VERSION "HINBNNNYYNNNYYNNNNNNNNNNNNYNNNYYYNNYNNNNNN/4//%%/4/'%**4NNN///"

NS_ :

BS_:

BU_: PSTED VMU
VAL_TABLE_ PSTED_IsolationControl 1 "Disable" 0 "Enable" ;
VAL_TABLE_ Wire_Isolation_Status 6 "Isolation failure flag (filtered & unfiltered)" 5 "Isolation failure flag (unfiltered) & reserved" 4 "Isolation failure flag (unfiltered)" 3 "Isolation failure flag & reserved" 2 "Isolation failure flag" 1 "reserved" 0 "ok" ;
VAL_TABLE_ DeviceStatus 15 "Overheat & Warning & Failure & Operating" 14 "Overheat & Warning & Failure" 13 "Overheat & Warning & Operating" 12 "Overheat & Warning" 11 "Overheat & Failure & Operating" 10 "Overheat & Failure" 9 "Overheat & Operating" 8 "Overheat" 7 "Warning & Failure & Operating" 6 "Warning & Failure" 5 "Warning & Operating" 4 "Warning" 3 "Failure & Operating" 2 "Failure" 1 "Operating" 0 "Idle" ;
VAL_TABLE_ Enable 1 "Enable" 0 "Disable" ;
VAL_TABLE_ Heartbeat_State 127 "PreOperational" 5 "Operational" 4 "Stopped" 0 "Bootup" ;

BO_ 1793 PSTED_Heartbeat: 1 Vector__XXX
 SG_ Toggle : 7|1@1+ (1,0) [0|1] "" Vector__XXX
 SG_ State : 0|7@1+ (1,0) [0|127] "" Vector__XXX

BO_ 660 PSTED_RefTorque: 8 VMU
 SG_ PSTED_RefFullCurrent : 16|16@1- (0.019837031,0) [-650.019831808|649.999994777] "A" Vector__XXX
 SG_ PSTED_RefElectricAngleOffset : 40|16@1- (0.010986663411359,0) [-360.010986663411|360] "deg" Vector__XXX
 SG_ PSTED_RefFluxCurrent : 32|8@1+ (0.2,0) [0|51] "A" Vector__XXX
 SG_ PSTED_RefTorque_16bit : 16|16@1- (0.0030518509476,0) [-100.003051850957|100.000000000009] "%"  PSTED
 SG_ PSTED_RefTorque_cmd : 0|8@1- (0.78740157,0) [-100.78740096|99.99999939] "%"  PSTED

BO_ 1153 PSTED_Errors: 8 PSTED
 SG_ PSTED_Warnings : 48|16@1+ (1,0) [0|65535] ""  VMU
 SG_ PSTED_ErrorFlags : 0|48@1+ (1,0) [0|281474976710655] ""  VMU

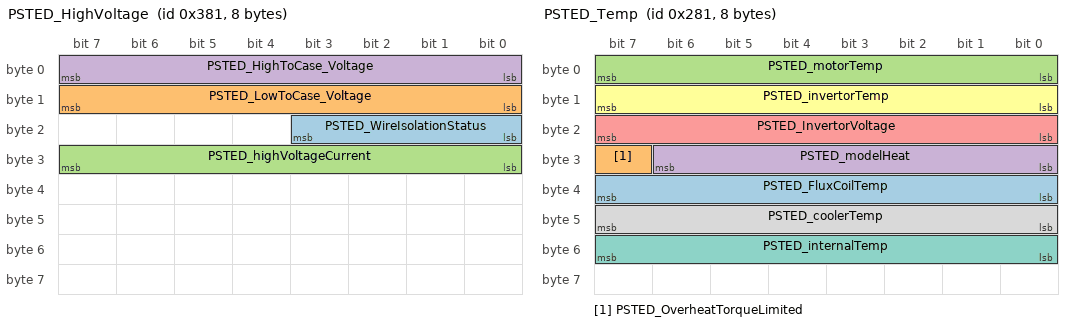
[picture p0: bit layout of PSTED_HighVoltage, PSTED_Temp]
BO_ 897 PSTED_HighVoltage: 8 PSTED
 SG_ PSTED_WireIsolationStatus : 16|4@1+ (1,0) [0|15] ""  VMU
 SG_ PSTED_LowToCase_Voltage : 8|8@1+ (6.35294117,0) [0|1619.99999835] "V"  VMU
 SG_ PSTED_highVoltageCurrent : 24|8@1- (1.5748031496,0) [-201.5748031488|199.9999999992] "A"  VMU
 SG_ PSTED_HighToCase_Voltage : 0|8@1+ (6.35294117,0) [0|1619.99999835] "V"  VMU

BO_ 641 PSTED_Temp: 8 PSTED
 SG_ PSTED_FluxCoilTemp : 32|8@1+ (1,-40) [-40|215] "°C" Vector__XXX
 SG_ PSTED_OverheatTorqueLimited : 31|1@1+ (1,0) [0|1] ""  VMU
 SG_ PSTED_motorTemp : 0|8@1+ (1,-40) [-40|215] "°C"  VMU
 SG_ PSTED_modelHeat : 24|7@1+ (0.7874015748,0) [0|99.9999999996] "%"  VMU
 SG_ PSTED_InvertorVoltage : 16|8@1+ (0.392156862745,0) [0|99.999999999975] "%"  VMU
 SG_ PSTED_invertorTemp : 8|8@1+ (1,-40) [-40|215] "°C"  VMU
 SG_ PSTED_internalTemp : 48|8@1+ (1,-40) [-40|215] "°C"  VMU
 SG_ PSTED_coolerTemp : 40|8@1+ (1,-40) [-40|215] "°C"  VMU

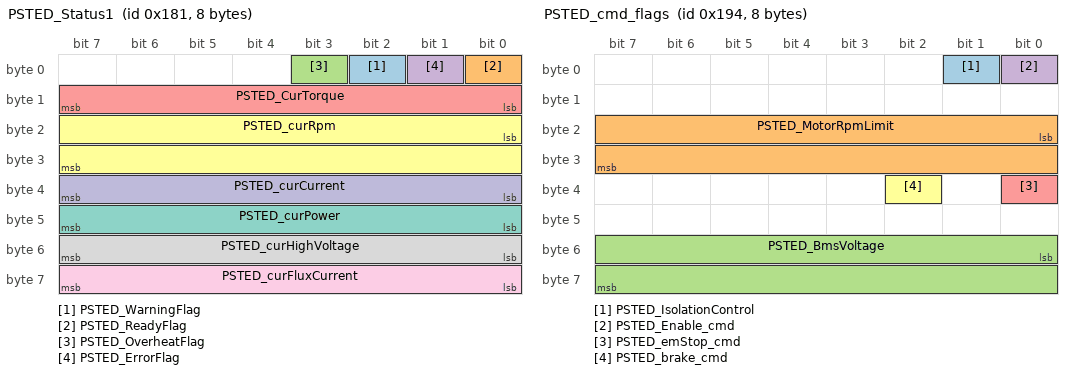
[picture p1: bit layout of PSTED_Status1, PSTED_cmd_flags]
BO_ 385 PSTED_Status1: 8 PSTED
 SG_ PSTED_WarningFlag : 2|1@1+ (1,0) [0|1] "" Vector__XXX
 SG_ PSTED_ReadyFlag : 0|1@1+ (1,0) [0|1] "" Vector__XXX
 SG_ PSTED_OverheatFlag : 3|1@1+ (1,0) [0|1] "" Vector__XXX
 SG_ PSTED_ErrorFlag : 1|1@1+ (1,0) [0|1] "" Vector__XXX
 SG_ PSTED_CurTorque : 8|8@1- (0.78740157,0) [-100.78740096|99.99999939] "%"  VMU
 SG_ PSTED_curRpm : 16|16@1- (0.24414807,0) [-8000.24395776|7999.99980969] "rpm"  VMU
 SG_ PSTED_curPower : 40|8@1- (1.1811023622,0) [-151.1811023616|149.9999999994] "kW"  VMU
 SG_ PSTED_curHighVoltage : 48|8@1+ (6.35294117,0) [0|1619.99999835] "V"  VMU
 SG_ PSTED_curFluxCurrent : 56|8@1+ (0.1372549019,0) [0|34.9999999845] "A"  VMU
 SG_ PSTED_curCurrent : 32|8@1- (5.118110236,0) [-655.118110208|649.999999972] "A"  VMU

BO_ 404 PSTED_cmd_flags: 8 VMU
 SG_ PSTED_IsolationControl : 1|1@1+ (1,0) [0|1] "" Vector__XXX
 SG_ PSTED_MotorRpmLimit : 16|16@1+ (1,0) [0|65535] "rpm" Vector__XXX
 SG_ PSTED_BmsVoltage : 48|16@1+ (0.1,0) [0|6553.5] "V"  PSTED
 SG_ PSTED_Enable_cmd : 0|1@1+ (1,0) [0|1] ""  PSTED
 SG_ PSTED_emStop_cmd : 32|1@1+ (1,0) [0|1] ""  PSTED
 SG_ PSTED_brake_cmd : 34|1@1+ (1,0) [0|1] ""  PSTED

CM_ SG_ 660 PSTED_RefFullCurrent "Reference torque for motor iverter. 16 bit resolution. Old inverters may bot use this field (use 8 bits instead)";
CM_ SG_ 660 PSTED_RefTorque_16bit "Reference torque for motor iverter. 16 bit resolution. Old inverters may bot use this field (use 8 bits instead)";
CM_ SG_ 404 PSTED_BmsVoltage "High voltage level measured by BMS. Sent to inverter to implement precharge logic.";
BA_DEF_ SG_  "GenSigStartValue" INT 0 0;
BA_DEF_ BO_  "CO_MsgCategory" INT 0 0;
BA_DEF_  "CO_MsgColourSupported" INT 0 1;
BA_DEF_  "CANopenApplProfile" INT 0 0;
BA_DEF_  "ProtocolType" STRING ;
BA_DEF_DEF_  "GenSigStartValue" 0;
BA_DEF_DEF_  "CO_MsgCategory" 0;
BA_DEF_DEF_  "CO_MsgColourSupported" 1;
BA_DEF_DEF_  "CANopenApplProfile" 301;
BA_DEF_DEF_  "ProtocolType" "CANopen";
BA_ "CO_MsgCategory" BO_ 1793 505;
BA_ "GenSigStartValue" SG_ 641 PSTED_FluxCoilTemp 40;
BA_ "GenSigStartValue" SG_ 641 PSTED_motorTemp 40;
BA_ "GenSigStartValue" SG_ 641 PSTED_invertorTemp 40;
BA_ "GenSigStartValue" SG_ 641 PSTED_internalTemp 40;
BA_ "GenSigStartValue" SG_ 641 PSTED_coolerTemp 40;
VAL_ 897 PSTED_WireIsolationStatus 6 "Isolation failure flag (filtered & unfiltered)" 5 "Isolation failure flag (unfiltered) & reserved" 4 "Isolation failure flag (unfiltered)" 3 "Isolation failure flag & reserved" 2 "Isolation failure flag" 1 "reserved" 0 "ok" ;
VAL_ 641 PSTED_OverheatTorqueLimited 1 "Enable" 0 "Disable" ;
VAL_ 404 PSTED_IsolationControl 1 "Disable" 0 "Enable" ;
VAL_ 404 PSTED_Enable_cmd 1 "Enable" 0 "Disable" ;
VAL_ 404 PSTED_emStop_cmd 1 "Enable" 0 "Disable" ;
VAL_ 404 PSTED_brake_cmd 1 "Enable" 0 "Disable" ;
